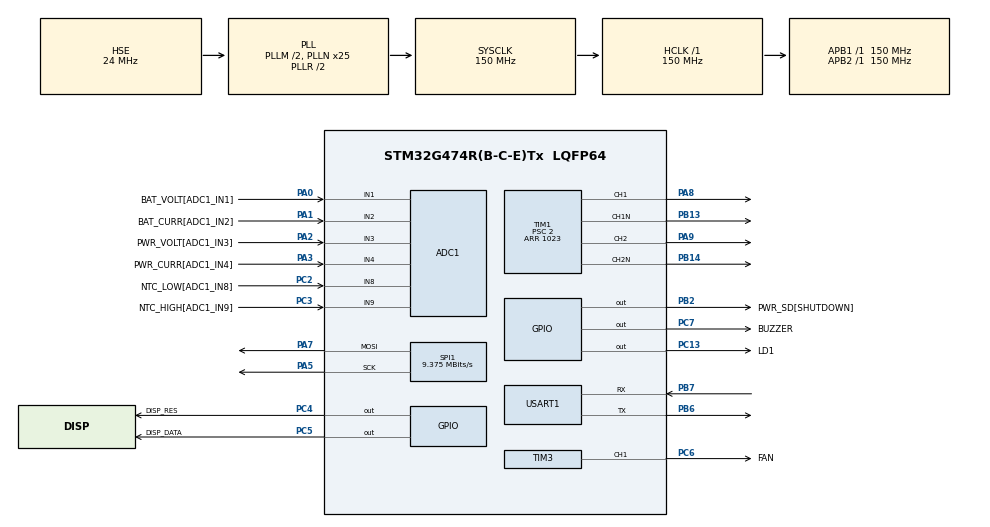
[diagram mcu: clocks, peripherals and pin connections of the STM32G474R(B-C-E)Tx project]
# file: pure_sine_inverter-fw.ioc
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ADC1.Channel-0\#ChannelRegularConversion=ADC_CHANNEL_1
ADC1.Channel-1\#ChannelRegularConversion=ADC_CHANNEL_2
ADC1.Channel-2\#ChannelRegularConversion=ADC_CHANNEL_3
ADC1.Channel-3\#ChannelRegularConversion=ADC_CHANNEL_4
ADC1.Channel-4\#ChannelRegularConversion=ADC_CHANNEL_8
ADC1.Channel-5\#ChannelRegularConversion=ADC_CHANNEL_9
ADC1.DMAContinuousRequests=ENABLE
ADC1.EOCSelection=ADC_EOC_SINGLE_CONV
ADC1.ExternalTrigConv=ADC_EXTERNALTRIG_T6_TRGO
ADC1.NbrOfConversion=6
ADC1.NbrOfConversionFlag=1
ADC1.OffsetNumber-0\#ChannelRegularConversion=ADC_OFFSET_NONE
ADC1.OffsetNumber-1\#ChannelRegularConversion=ADC_OFFSET_NONE
ADC1.OffsetNumber-2\#ChannelRegularConversion=ADC_OFFSET_NONE
ADC1.OffsetNumber-3\#ChannelRegularConversion=ADC_OFFSET_NONE
ADC1.OffsetNumber-4\#ChannelRegularConversion=ADC_OFFSET_NONE
ADC1.OffsetNumber-5\#ChannelRegularConversion=ADC_OFFSET_NONE
ADC1.Rank-0\#ChannelRegularConversion=1
ADC1.Rank-1\#ChannelRegularConversion=2
ADC1.Rank-2\#ChannelRegularConversion=3
ADC1.Rank-3\#ChannelRegularConversion=4
ADC1.Rank-4\#ChannelRegularConversion=5
ADC1.Rank-5\#ChannelRegularConversion=6
ADC1.SamplingTime-0\#ChannelRegularConversion=ADC_SAMPLETIME_47CYCLES_5
ADC1.SamplingTime-1\#ChannelRegularConversion=ADC_SAMPLETIME_47CYCLES_5
ADC1.SamplingTime-2\#ChannelRegularConversion=ADC_SAMPLETIME_47CYCLES_5
ADC1.SamplingTime-3\#ChannelRegularConversion=ADC_SAMPLETIME_47CYCLES_5
ADC1.SamplingTime-4\#ChannelRegularConversion=ADC_SAMPLETIME_47CYCLES_5
ADC1.SamplingTime-5\#ChannelRegularConversion=ADC_SAMPLETIME_47CYCLES_5
ADC1.master=1
Dma.ADC1.0.Direction=DMA_PERIPH_TO_MEMORY
Dma.ADC1.0.EventEnable=DISABLE
Dma.ADC1.0.Instance=DMA1_Channel3
Dma.ADC1.0.MemDataAlignment=DMA_MDATAALIGN_HALFWORD
Dma.ADC1.0.MemInc=DMA_MINC_ENABLE
Dma.ADC1.0.Mode=DMA_CIRCULAR
Dma.ADC1.0.PeriphDataAlignment=DMA_PDATAALIGN_HALFWORD
Dma.ADC1.0.PeriphInc=DMA_PINC_DISABLE
Dma.ADC1.0.Polarity=HAL_DMAMUX_REQ_GEN_RISING
Dma.ADC1.0.Priority=DMA_PRIORITY_LOW
Dma.ADC1.0.RequestNumber=1
Dma.ADC1.0.SignalID=NONE
Dma.ADC1.0.SyncEnable=DISABLE
Dma.ADC1.0.SyncPolarity=HAL_DMAMUX_SYNC_NO_EVENT
Dma.ADC1.0.SyncRequestNumber=1
Dma.ADC1.0.SyncSignalID=NONE
Dma.Request0=ADC1
Dma.Request1=TIM4_CH1
Dma.Request2=TIM4_CH2
Dma.TIM4_CH1.1.Direction=DMA_MEMORY_TO_PERIPH
Dma.TIM4_CH1.1.EventEnable=DISABLE
Dma.TIM4_CH1.1.Instance=DMA1_Channel1
Dma.TIM4_CH1.1.MemDataAlignment=DMA_MDATAALIGN_WORD
Dma.TIM4_CH1.1.MemInc=DMA_MINC_ENABLE
Dma.TIM4_CH1.1.Mode=DMA_CIRCULAR
Dma.TIM4_CH1.1.PeriphDataAlignment=DMA_PDATAALIGN_WORD
Dma.TIM4_CH1.1.PeriphInc=DMA_PINC_DISABLE
Dma.TIM4_CH1.1.Polarity=HAL_DMAMUX_REQ_GEN_RISING
Dma.TIM4_CH1.1.Priority=DMA_PRIORITY_HIGH
Dma.TIM4_CH1.1.RequestNumber=1
Dma.TIM4_CH1.1.SignalID=NONE
Dma.TIM4_CH1.1.SyncEnable=DISABLE
Dma.TIM4_CH1.1.SyncPolarity=HAL_DMAMUX_SYNC_NO_EVENT
Dma.TIM4_CH1.1.SyncRequestNumber=1
Dma.TIM4_CH1.1.SyncSignalID=NONE
Dma.TIM4_CH2.2.Direction=DMA_MEMORY_TO_PERIPH
Dma.TIM4_CH2.2.EventEnable=DISABLE
Dma.TIM4_CH2.2.Instance=DMA1_Channel2
Dma.TIM4_CH2.2.MemDataAlignment=DMA_MDATAALIGN_WORD
Dma.TIM4_CH2.2.MemInc=DMA_MINC_ENABLE
Dma.TIM4_CH2.2.Mode=DMA_CIRCULAR
Dma.TIM4_CH2.2.PeriphDataAlignment=DMA_PDATAALIGN_WORD
Dma.TIM4_CH2.2.PeriphInc=DMA_PINC_DISABLE
Dma.TIM4_CH2.2.Polarity=HAL_DMAMUX_REQ_GEN_RISING
Dma.TIM4_CH2.2.Priority=DMA_PRIORITY_HIGH
Dma.TIM4_CH2.2.RequestNumber=1
Dma.TIM4_CH2.2.SignalID=NONE
Dma.TIM4_CH2.2.SyncEnable=DISABLE
Dma.TIM4_CH2.2.SyncPolarity=HAL_DMAMUX_SYNC_NO_EVENT
Dma.TIM4_CH2.2.SyncRequestNumber=1
Dma.TIM4_CH2.2.SyncSignalID=NONE
Mcu.Family=STM32G4
Mcu.Name=STM32G474R(B-C-E)Tx
Mcu.Package=LQFP64
NVIC.DMA1_Channel1_IRQn=true\:1\:0\:true\:false\:true\:false\:true\:true
NVIC.DMA1_Channel2_IRQn=true\:0\:0\:false\:false\:true\:false\:true\:true
NVIC.DMA1_Channel3_IRQn=true\:0\:0\:false\:false\:true\:false\:true\:true
NVIC.PriorityGroup=NVIC_PRIORITYGROUP_4
PA0.GPIO_Label=BAT_VOLT[ADC1_IN1]
PA0.Mode=IN1-Single-Ended
PA0.Signal=ADC1_IN1
PA1.GPIO_Label=BAT_CURR[ADC1_IN2]
PA1.Mode=IN2-Single-Ended
PA1.Signal=ADC1_IN2
PA13.Mode=Trace_Asynchronous_SW
PA13.Signal=SYS_JTMS-SWDIO
PA14.Mode=Trace_Asynchronous_SW
PA14.Signal=SYS_JTCK-SWCLK
PA2.GPIO_Label=PWR_VOLT[ADC1_IN3]
PA2.Mode=IN3-Single-Ended
PA2.Signal=ADC1_IN3
PA3.GPIO_Label=PWR_CURR[ADC1_IN4]
PA3.Mode=IN4-Single-Ended
PA3.Signal=ADC1_IN4
PA5.GPIO_Speed=GPIO_SPEED_FREQ_VERY_HIGH
PA5.Mode=TX_Only_Simplex_Unidirect_Master
PA5.Signal=SPI1_SCK
PA7.GPIO_Speed=GPIO_SPEED_FREQ_VERY_HIGH
PA7.Mode=TX_Only_Simplex_Unidirect_Master
PA7.Signal=SPI1_MOSI
PA8.Signal=S_TIM1_CH1
PA9.Signal=S_TIM1_CH2
PB13.Mode=PWM Generation1 CH1 CH1N
PB13.Signal=TIM1_CH1N
PB14.Mode=PWM Generation2 CH2 CH2N
PB14.Signal=TIM1_CH2N
PB2.GPIO_Label=PWR_SD[SHUTDOWN]
PB2.GPIO_Speed=GPIO_SPEED_FREQ_VERY_HIGH
PB2.Signal=GPIO_Output
PB3.Mode=Trace_Asynchronous_SW
PB3.Signal=SYS_JTDO-SWO
PB6.Mode=Asynchronous
PB6.Signal=USART1_TX
PB7.Mode=Asynchronous
PB7.Signal=USART1_RX
PC13.GPIO_Label=LD1
PC13.Signal=GPIO_Output
PC2.GPIO_Label=NTC_LOW[ADC1_IN8]
PC2.Mode=IN8-Single-Ended
PC2.Signal=ADC1_IN8
PC3.GPIO_Label=NTC_HIGH[ADC1_IN9]
PC3.Mode=IN9-Single-Ended
PC3.Signal=ADC1_IN9
PC4.GPIO_Label=DISP_RES
PC4.GPIO_Speed=GPIO_SPEED_FREQ_VERY_HIGH
PC4.Signal=GPIO_Output
PC5.GPIO_Label=DISP_DATA
PC5.GPIO_Speed=GPIO_SPEED_FREQ_VERY_HIGH
PC5.Signal=GPIO_Output
PC6.GPIO_Label=FAN
PC6.Signal=S_TIM3_CH1
PC7.GPIO_Label=BUZZER
PC7.GPIO_Speed=GPIO_SPEED_FREQ_VERY_HIGH
PC7.Signal=GPIO_Output
PF0-OSC_IN.Mode=HSE-External-Oscillator
PF0-OSC_IN.Signal=RCC_OSC_IN
PF1-OSC_OUT.Mode=HSE-External-Oscillator
PF1-OSC_OUT.Signal=RCC_OSC_OUT
ProjectManager.HeapSize=0x200
ProjectManager.StackSize=0x400
ProjectManager.TargetToolchain=STM32CubeIDE
RCC.ADC12Freq_Value=150000000
RCC.ADC345Freq_Value=150000000
RCC.AHBFreq_Value=150000000
RCC.APB1Freq_Value=150000000
RCC.APB1TimFreq_Value=150000000
RCC.APB2Freq_Value=150000000
RCC.APB2TimFreq_Value=150000000
RCC.CortexFreq_Value=150000000
RCC.EXTERNAL_CLOCK_VALUE=12288000
RCC.HCLKFreq_Value=150000000
RCC.HSE_VALUE=24000000
RCC.HSI48_VALUE=48000000
RCC.HSI_VALUE=16000000
RCC.LSE_VALUE=32768
RCC.PLLM=RCC_PLLM_DIV2
RCC.PLLN=25
RCC.PLLSourceVirtual=RCC_PLLSOURCE_HSE
RCC.SYSCLKFreq_VALUE=150000000
RCC.SYSCLKSource=RCC_SYSCLKSOURCE_PLLCLK
RCC.USBFreq_Value=150000000
RCC.VCOOutputFreq_Value=300000000
SH.S_TIM1_CH1.0=TIM1_CH1,PWM Generation1 CH1 CH1N
SH.S_TIM1_CH2.0=TIM1_CH2,PWM Generation2 CH2 CH2N
SH.S_TIM3_CH1.0=TIM3_CH1,PWM Generation1 CH1
SPI1.BaudRatePrescaler=SPI_BAUDRATEPRESCALER_16
SPI1.CLKPolarity=SPI_POLARITY_HIGH
SPI1.CalculateBaudRate=9.375 MBits/s
SPI1.DataSize=SPI_DATASIZE_8BIT
SPI1.Direction=SPI_DIRECTION_2LINES
SPI1.Mode=SPI_MODE_MASTER
SPI1.VirtualType=VM_MASTER
TIM1.Break2Polarity=TIM_BREAK2POLARITY_HIGH
TIM1.Channel-PWM\ Generation1\ CH1\ CH1N=TIM_CHANNEL_1
TIM1.Channel-PWM\ Generation2\ CH2\ CH2N=TIM_CHANNEL_2
TIM1.OCNPolarity_1=TIM_OCNPOLARITY_LOW
TIM1.OCNPolarity_2=TIM_OCNPOLARITY_LOW
TIM1.PeriodNoDither=1023
TIM1.Prescaler=2
TIM3.Channel-PWM\ Generation1\ CH1=TIM_CHANNEL_1
TIM3.PeriodNoDither=99
TIM3.Prescaler=1499
TIM4.AutoReloadPreload=TIM_AUTORELOAD_PRELOAD_ENABLE
TIM4.Channel-Output\ Compare1\ No\ Output=TIM_CHANNEL_1
TIM4.Channel-Output\ Compare2\ No\ Output=TIM_CHANNEL_2
TIM4.PeriodNoDither=100
TIM6.PeriodNoDither=99
TIM6.Prescaler=1499
TIM6.TIM_MasterOutputTrigger=TIM_TRGO_UPDATE
USART1.VirtualMode-Asynchronous=VM_ASYNC
VP_SYS_VS_DBSignals.Mode=DisableDeadBatterySignals
VP_TIM1_VS_ClockSourceINT.Mode=Internal
VP_TIM3_VS_ClockSourceINT.Mode=Internal
VP_TIM4_VS_ClockSourceINT.Mode=Internal
VP_TIM4_VS_no_output1.Mode=Output Compare1 No Output
VP_TIM4_VS_no_output2.Mode=Output Compare2 No Output
VP_TIM6_VS_ClockSourceINT.Mode=Enable_Timer
board=custom

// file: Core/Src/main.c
/*******************************************************************************
 * @file main.c
 * @brief main application of heimdall 250w inverter.
 *
 * Designed by Heimdall
 *******************************************************************************
 *     _   _ _____ ___ __  __ ____    _    _     _
 *    | | | | ____|_ _|  \/  |  _ \  / \  | |   | |
 *    | |_| |  _|  | || |\/| | | | |/ _ \ | |   | |
 *    |  _  | |___ | || |  | | |_| / ___ \| |___| |___
 *    |_| |_|_____|___|_|  |_|____/_/   \_|_____|_____|
 *
 *
 *     ___ _   ___     _______ ____ _____ _____ ____
 *    |_ _| \ | \ \   / | ____|  _ |_   _| ____|  _ \
 *     | ||  \| |\ \ / /|  _| | |_) || | |  _| | |_) |
 *     | || |\  | \ V / | |___|  _ < | | | |___|  _ <
 *    |___|_| \_|  \_/  |_____|_| \_\|_| |_____|_| \_\
 *
 ******************************************************************************/

#include "main.h"
#include "adc.h"
#include "dma.h"
#include "spi.h"
#include "tim.h"
#include "usart.h"
#include "gpio.h"

/* USER CODE BEGIN Includes */
#include "pwr.h"
#include "display.h"
#include "inverter.h"
/* USER CODE END Includes */

void SystemClock_Config(void);

int main(void)
{

  /* MCU Configuration--------------------------------------------------------*/

  /* Reset of all peripherals, Initializes the Flash interface and the Systick. */
  HAL_Init();

  /* Configure the system clock */
  SystemClock_Config();

  /* Initialize all configured peripherals */
  MX_GPIO_Init();
  MX_DMA_Init();
  MX_TIM1_Init();
  MX_ADC1_Init();
  MX_USART1_UART_Init();
  MX_SPI1_Init();
  MX_TIM3_Init();
  MX_TIM6_Init();
  MX_TIM4_Init();
  /* USER CODE BEGIN 2 */
  pwr_set_gate_driver_off();
  /* initialize inverter application */
  inverter_init();
  /* USER CODE END 2 */

  /* Infinite loop */
  /* USER CODE BEGIN WHILE */
  while (1)
  {

	   /* run inverter application */
	 inverter_run();

    /* USER CODE END WHILE */

  }
}

void SystemClock_Config(void)
{
  RCC_OscInitTypeDef RCC_OscInitStruct = {0};
  RCC_ClkInitTypeDef RCC_ClkInitStruct = {0};

  /** Configure the main internal regulator output voltage
  */
  HAL_PWREx_ControlVoltageScaling(PWR_REGULATOR_VOLTAGE_SCALE1);

  /** Initializes the RCC Oscillators according to the specified parameters
  * in the RCC_OscInitTypeDef structure.
  */
  RCC_OscInitStruct.OscillatorType = RCC_OSCILLATORTYPE_HSE;
  RCC_OscInitStruct.HSEState = RCC_HSE_ON;
  RCC_OscInitStruct.PLL.PLLState = RCC_PLL_ON;
  RCC_OscInitStruct.PLL.PLLSource = RCC_PLLSOURCE_HSE;
  RCC_OscInitStruct.PLL.PLLM = RCC_PLLM_DIV2;
  RCC_OscInitStruct.PLL.PLLN = 25;
  RCC_OscInitStruct.PLL.PLLP = RCC_PLLP_DIV2;
  RCC_OscInitStruct.PLL.PLLQ = RCC_PLLQ_DIV2;
  RCC_OscInitStruct.PLL.PLLR = RCC_PLLR_DIV2;
  if (HAL_RCC_OscConfig(&RCC_OscInitStruct) != HAL_OK)
  {
    Error_Handler();
  }

  /** Initializes the CPU, AHB and APB buses clocks
  */
  RCC_ClkInitStruct.ClockType = RCC_CLOCKTYPE_HCLK|RCC_CLOCKTYPE_SYSCLK
                              |RCC_CLOCKTYPE_PCLK1|RCC_CLOCKTYPE_PCLK2;
  RCC_ClkInitStruct.SYSCLKSource = RCC_SYSCLKSOURCE_PLLCLK;
  RCC_ClkInitStruct.AHBCLKDivider = RCC_SYSCLK_DIV1;
  RCC_ClkInitStruct.APB1CLKDivider = RCC_HCLK_DIV1;
  RCC_ClkInitStruct.APB2CLKDivider = RCC_HCLK_DIV1;

  if (HAL_RCC_ClockConfig(&RCC_ClkInitStruct, FLASH_LATENCY_4) != HAL_OK)
  {
    Error_Handler();
  }
}

void Error_Handler(void)
{
  __disable_irq();
  while (1)
  {
  }
}

/************************ (C) COPYRIGHT Heimdall *****************END OF FILE****/
